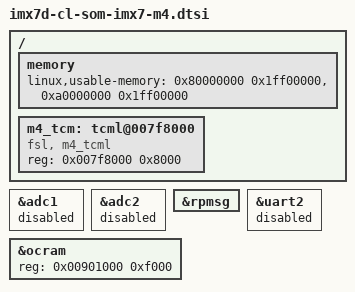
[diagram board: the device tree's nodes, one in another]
/*
 * Support for CompuLab CL-SOM-iMX7 System-on-Module Cortex-M4
 *
 * Copyright (C) 2017 CompuLab Ltd. - http://www.compulab.co.il/
 * Author: Nikita Kiryanov <nikita@compulab.co.il>
 *
 * This program is free software; you can redistribute it and/or modify
 * it under the terms of the GNU General Public License version 2 as
 * published by the Free Software Foundation.
 */

/ {
	/* usable memory */
	memory {
		linux,usable-memory = <0x80000000 0x1ff00000>,
					<0xa0000000 0x1ff00000>;
	};

	m4_tcm: tcml@007f8000 {
		compatible = "fsl, m4_tcml";
		reg = <0x007f8000 0x8000>;
	};
};

&adc1 {
	status = "disabled";
};

&adc2 {
	status = "disabled";
};

&rpmsg {
	status = "okay";
};

&uart2 {
	status = "disabled";
};

&ocram {
	reg = <0x00901000 0xf000>;
};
